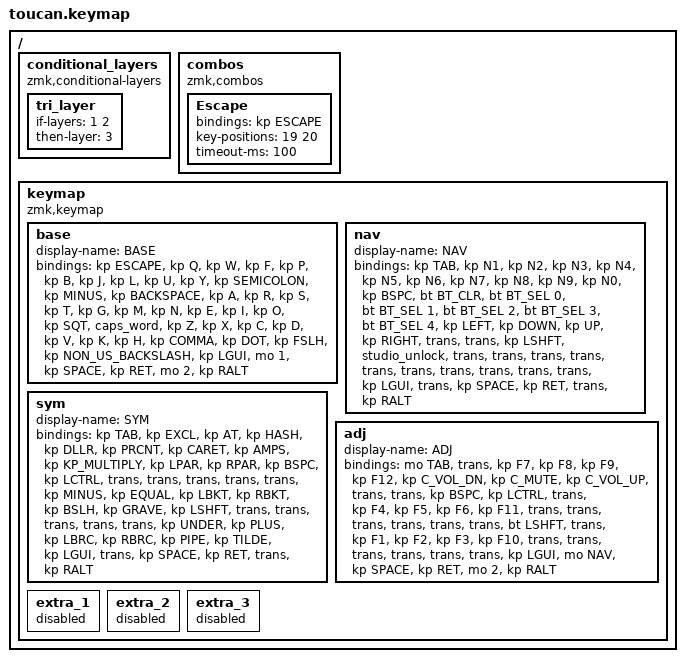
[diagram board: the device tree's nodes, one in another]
#include <behaviors.dtsi>
#include <dt-bindings/zmk/bt.h>
#include <dt-bindings/zmk/keys.h>

#define BASE 0
#define NAV  1
#define SYM  2
#define ADJ  3

/ {
    conditional_layers {
        compatible = "zmk,conditional-layers";

        tri_layer {
            if-layers = <1 2>;
            then-layer = <3>;
        };
    };

    combos {
        compatible = "zmk,combos";

        Escape {
            bindings = <&kp ESCAPE>;
            key-positions = <19 20>;
            timeout-ms = <100>;
        };
    };

    keymap {
        compatible = "zmk,keymap";

        base {
            display-name = "BASE";
            bindings = <
&kp ESCAPE  &kp Q  &kp W  &kp F  &kp P  &kp B  &kp J  &kp L  &kp U  &kp Y  &kp SEMICOLON  &kp MINUS  &kp BACKSPACE  &kp A  &kp R  &kp S  &kp T  &kp G  &kp M  &kp N  &kp E  &kp I  &kp O  &kp SQT  &caps_word  &kp Z  &kp X  &kp C  &kp D  &kp V  &kp K  &kp H  &kp COMMA  &kp DOT  &kp FSLH  &kp NON_US_BACKSLASH  &kp LGUI  &mo 1  &kp SPACE  &kp RET  &mo 2  &kp RALT
            >;
        };

        nav {
            display-name = "NAV";
            bindings = <
&kp TAB  &kp N1  &kp N2  &kp N3  &kp N4  &kp N5  &kp N6  &kp N7  &kp N8  &kp N9  &kp N0  &kp BSPC  &bt BT_CLR  &bt BT_SEL 0  &bt BT_SEL 1  &bt BT_SEL 2  &bt BT_SEL 3  &bt BT_SEL 4  &kp LEFT  &kp DOWN  &kp UP  &kp RIGHT  &trans  &trans  &kp LSHFT  &studio_unlock  &trans  &trans  &trans  &trans  &trans  &trans  &trans  &trans  &trans  &trans  &kp LGUI  &trans  &kp SPACE  &kp RET  &trans  &kp RALT
            >;
        };

        sym {
            display-name = "SYM";
            bindings = <
&kp TAB  &kp EXCL  &kp AT  &kp HASH  &kp DLLR  &kp PRCNT  &kp CARET  &kp AMPS  &kp KP_MULTIPLY  &kp LPAR  &kp RPAR  &kp BSPC  &kp LCTRL  &trans  &trans  &trans  &trans  &trans  &kp MINUS  &kp EQUAL  &kp LBKT  &kp RBKT  &kp BSLH  &kp GRAVE  &kp LSHFT  &trans  &trans  &trans  &trans  &trans  &kp UNDER  &kp PLUS  &kp LBRC  &kp RBRC  &kp PIPE  &kp TILDE  &kp LGUI  &trans  &kp SPACE  &kp RET  &trans  &kp RALT
            >;
        };

        adj {
            display-name = "ADJ";
            bindings = <
&mo TAB  &trans  &kp F7  &kp F8  &kp F9  &kp F12  &kp C_VOL_DN  &kp C_MUTE  &kp C_VOL_UP  &trans  &trans  &kp BSPC  &kp LCTRL  &trans  &kp F4  &kp F5  &kp F6  &kp F11  &trans  &trans  &trans  &trans  &trans  &trans  &bt LSHFT  &trans  &kp F1  &kp F2  &kp F3  &kp F10  &trans  &trans  &trans  &trans  &trans  &trans  &kp LGUI  &mo NAV  &kp SPACE  &kp RET  &mo 2  &kp RALT
            >;
        };

        extra_1 { status = "reserved"; };

        extra_2 { status = "reserved"; };

        extra_3 { status = "reserved"; };
    };
};
